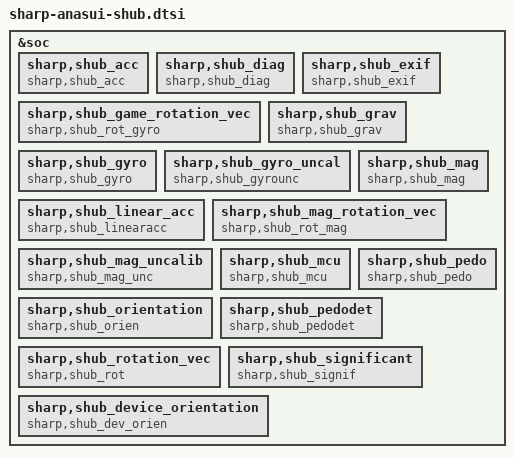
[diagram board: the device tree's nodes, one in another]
/*
 * Copyright (c) 2018, The Linux Foundation. All rights reserved.
 *
 * This program is free software; you can redistribute it and/or modify
 * it under the terms of the GNU General Public License version 2 and
 * only version 2 as published by the Free Software Foundation.
 *
 * This program is distributed in the hope that it will be useful,
 * but WITHOUT ANY WARRANTY; without even the implied warranty of
 * MERCHANTABILITY or FITNESS FOR A PARTICULAR PURPOSE.  See the
 * GNU General Public License for more details.
 */

/*****************************************/
/*  SHARP Device Drivers SensorHub       */
/*****************************************/
&soc {
	sharp,shub_acc {
		status = "ok";
		compatible = "sharp,shub_acc";
	};

	sharp,shub_diag {
		status = "ok";
		compatible = "sharp,shub_diag";
	};

	sharp,shub_exif {
		status = "ok";
		compatible = "sharp,shub_exif";
	};

	sharp,shub_game_rotation_vec {
		status = "ok";
		compatible = "sharp,shub_rot_gyro";
	};

	sharp,shub_grav {
		status = "ok";
		compatible = "sharp,shub_grav";
	};

	sharp,shub_gyro {
		status = "ok";
		compatible = "sharp,shub_gyro";
	};

	sharp,shub_gyro_uncal {
		status = "ok";
		compatible = "sharp,shub_gyrounc";
	};

	sharp,shub_linear_acc {
		status = "ok";
		compatible = "sharp,shub_linearacc";
	};

	sharp,shub_mag {
		status = "ok";
		compatible = "sharp,shub_mag";
	};

	sharp,shub_mag_rotation_vec {
		status = "ok";
		compatible = "sharp,shub_rot_mag";
	};

	sharp,shub_mag_uncalib {
		status = "ok";
		compatible = "sharp,shub_mag_unc";
	};

	sharp,shub_mcu {
		status = "ok";
		compatible = "sharp,shub_mcu";
	};

	sharp,shub_orientation {
		status = "ok";
		compatible = "sharp,shub_orien";
	};

	sharp,shub_pedo {
		status = "ok";
		compatible = "sharp,shub_pedo";
	};

	sharp,shub_pedodet {
		status = "ok";
		compatible = "sharp,shub_pedodet";
	};

	sharp,shub_rotation_vec {
		status = "ok";
		compatible = "sharp,shub_rot";
	};

	sharp,shub_significant {
		status = "ok";
		compatible = "sharp,shub_signif";
	};

	sharp,shub_device_orientation {
		status = "ok";
		compatible = "sharp,shub_dev_orien";
	};
};
